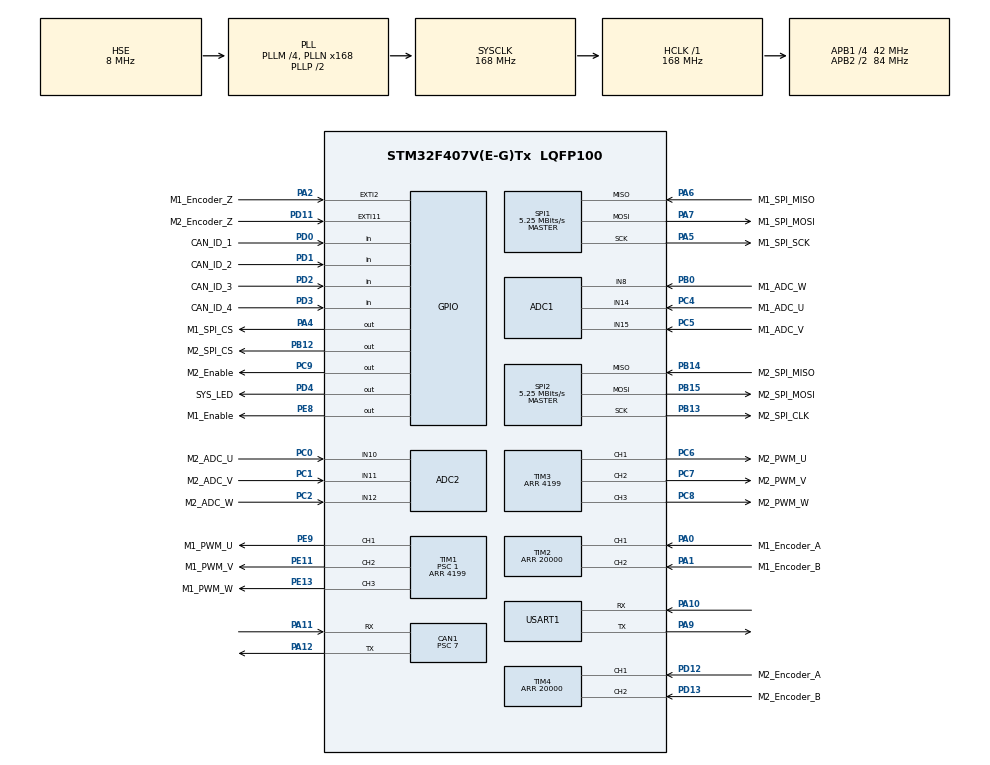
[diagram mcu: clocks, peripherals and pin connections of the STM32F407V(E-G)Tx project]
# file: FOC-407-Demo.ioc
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ADC1.Channel-0\#ChannelRegularConversion=ADC_CHANNEL_14
ADC1.Channel-1\#ChannelRegularConversion=ADC_CHANNEL_15
ADC1.Channel-2\#ChannelRegularConversion=ADC_CHANNEL_8
ADC1.ClockPrescaler=ADC_CLOCK_SYNC_PCLK_DIV4
ADC1.ContinuousConvMode=DISABLE
ADC1.DMAContinuousRequests=ENABLE
ADC1.EOCSelection=ADC_EOC_SEQ_CONV
ADC1.InjNumberOfConversion=0
ADC1.NbrOfConversion=3
ADC1.NbrOfConversionFlag=1
ADC1.Rank-0\#ChannelRegularConversion=1
ADC1.Rank-1\#ChannelRegularConversion=2
ADC1.Rank-2\#ChannelRegularConversion=3
ADC1.SamplingTime-0\#ChannelRegularConversion=ADC_SAMPLETIME_3CYCLES
ADC1.SamplingTime-1\#ChannelRegularConversion=ADC_SAMPLETIME_3CYCLES
ADC1.SamplingTime-2\#ChannelRegularConversion=ADC_SAMPLETIME_3CYCLES
ADC1.ScanConvMode=ENABLE
ADC1.master=1
ADC2.Channel-0\#ChannelRegularConversion=ADC_CHANNEL_10
ADC2.Channel-1\#ChannelRegularConversion=ADC_CHANNEL_11
ADC2.Channel-2\#ChannelRegularConversion=ADC_CHANNEL_12
ADC2.DMAContinuousRequests=ENABLE
ADC2.EOCSelection=ADC_EOC_SEQ_CONV
ADC2.NbrOfConversion=3
ADC2.NbrOfConversionFlag=1
ADC2.Rank-0\#ChannelRegularConversion=1
ADC2.Rank-1\#ChannelRegularConversion=2
ADC2.Rank-2\#ChannelRegularConversion=3
ADC2.SamplingTime-0\#ChannelRegularConversion=ADC_SAMPLETIME_3CYCLES
ADC2.SamplingTime-1\#ChannelRegularConversion=ADC_SAMPLETIME_3CYCLES
ADC2.SamplingTime-2\#ChannelRegularConversion=ADC_SAMPLETIME_3CYCLES
ADC2.ScanConvMode=ENABLE
CAN1.BS1=CAN_BS1_5TQ
CAN1.BS2=CAN_BS2_6TQ
CAN1.CalculateTimeQuantum=166.66666666666669
CAN1.Mode=CAN_MODE_NORMAL
CAN1.Prescaler=7
Dma.ADC1.0.Direction=DMA_PERIPH_TO_MEMORY
Dma.ADC1.0.FIFOMode=DMA_FIFOMODE_DISABLE
Dma.ADC1.0.Instance=DMA2_Stream0
Dma.ADC1.0.MemDataAlignment=DMA_MDATAALIGN_WORD
Dma.ADC1.0.MemInc=DMA_MINC_ENABLE
Dma.ADC1.0.Mode=DMA_CIRCULAR
Dma.ADC1.0.PeriphDataAlignment=DMA_PDATAALIGN_WORD
Dma.ADC1.0.PeriphInc=DMA_PINC_DISABLE
Dma.ADC1.0.Priority=DMA_PRIORITY_HIGH
Dma.ADC2.1.Direction=DMA_PERIPH_TO_MEMORY
Dma.ADC2.1.FIFOMode=DMA_FIFOMODE_DISABLE
Dma.ADC2.1.Instance=DMA2_Stream2
Dma.ADC2.1.MemDataAlignment=DMA_MDATAALIGN_WORD
Dma.ADC2.1.MemInc=DMA_MINC_ENABLE
Dma.ADC2.1.Mode=DMA_CIRCULAR
Dma.ADC2.1.PeriphDataAlignment=DMA_PDATAALIGN_WORD
Dma.ADC2.1.PeriphInc=DMA_PINC_DISABLE
Dma.ADC2.1.Priority=DMA_PRIORITY_HIGH
Dma.Request0=ADC1
Dma.Request1=ADC2
Mcu.Family=STM32F4
Mcu.Name=STM32F407V(E-G)Tx
Mcu.Package=LQFP100
NVIC.CAN1_RX0_IRQn=true\:7\:0\:true\:false\:true\:true\:true
NVIC.DMA2_Stream0_IRQn=true\:3\:0\:true\:false\:true\:true\:true
NVIC.DMA2_Stream2_IRQn=true\:5\:0\:true\:false\:true\:false\:true
NVIC.EXTI15_10_IRQn=true\:2\:0\:true\:false\:true\:true\:true
NVIC.EXTI2_IRQn=true\:1\:0\:true\:false\:true\:true\:true
NVIC.PriorityGroup=NVIC_PRIORITYGROUP_4
NVIC.TIM1_UP_TIM10_IRQn=true\:4\:0\:true\:false\:true\:true\:true
NVIC.TIM3_IRQn=true\:6\:0\:true\:false\:true\:true\:true
NVIC.USART1_IRQn=true\:8\:0\:true\:false\:true\:true\:true
PA0-WKUP.GPIO_Label=M1_Encoder_A
PA0-WKUP.Signal=S_TIM2_CH1_ETR
PA1.GPIO_Label=M1_Encoder_B
PA1.Signal=S_TIM2_CH2
PA10.Mode=Asynchronous
PA10.Signal=USART1_RX
PA11.Mode=Master
PA11.Signal=CAN1_RX
PA12.Mode=Master
PA12.Signal=CAN1_TX
PA13.Mode=Serial_Wire
PA13.Signal=SYS_JTMS-SWDIO
PA14.Mode=Serial_Wire
PA14.Signal=SYS_JTCK-SWCLK
PA2.GPIO_Label=M1_Encoder_Z
PA2.Signal=GPXTI2
PA4.GPIO_Label=M1_SPI_CS
PA4.GPIO_PuPd=GPIO_PULLUP
PA4.GPIO_Speed=GPIO_SPEED_FREQ_HIGH
PA4.PinState=GPIO_PIN_SET
PA4.Signal=GPIO_Output
PA5.GPIO_Label=M1_SPI_SCK
PA5.Mode=Full_Duplex_Master
PA5.Signal=SPI1_SCK
PA6.GPIO_Label=M1_SPI_MISO
PA6.Mode=Full_Duplex_Master
PA6.Signal=SPI1_MISO
PA7.GPIO_Label=M1_SPI_MOSI
PA7.Mode=Full_Duplex_Master
PA7.Signal=SPI1_MOSI
PA9.Mode=Asynchronous
PA9.Signal=USART1_TX
PB0.GPIO_Label=M1_ADC_W
PB0.Signal=ADCx_IN8
PB12.GPIO_Label=M2_SPI_CS
PB12.GPIO_PuPd=GPIO_PULLUP
PB12.GPIO_Speed=GPIO_SPEED_FREQ_HIGH
PB12.PinState=GPIO_PIN_SET
PB12.Signal=GPIO_Output
PB13.GPIO_Label=M2_SPI_CLK
PB13.Mode=Full_Duplex_Master
PB13.Signal=SPI2_SCK
PB14.GPIO_Label=M2_SPI_MISO
PB14.Mode=Full_Duplex_Master
PB14.Signal=SPI2_MISO
PB15.GPIO_Label=M2_SPI_MOSI
PB15.Mode=Full_Duplex_Master
PB15.Signal=SPI2_MOSI
PC0.GPIO_Label=M2_ADC_U
PC0.Signal=ADCx_IN10
PC1.GPIO_Label=M2_ADC_V
PC1.Signal=ADCx_IN11
PC2.GPIO_Label=M2_ADC_W
PC2.Signal=ADCx_IN12
PC4.GPIO_Label=M1_ADC_U
PC4.Signal=ADCx_IN14
PC5.GPIO_Label=M1_ADC_V
PC5.Signal=ADCx_IN15
PC6.GPIO_Label=M2_PWM_U
PC6.Signal=S_TIM3_CH1
PC7.GPIO_Label=M2_PWM_V
PC7.Signal=S_TIM3_CH2
PC8.GPIO_Label=M2_PWM_W
PC8.Signal=S_TIM3_CH3
PC9.GPIO_Label=M2_Enable
PC9.Signal=GPIO_Output
PD0.GPIO_Label=CAN_ID_1
PD0.GPIO_PuPd=GPIO_PULLUP
PD0.Signal=GPIO_Input
PD1.GPIO_Label=CAN_ID_2
PD1.GPIO_PuPd=GPIO_PULLUP
PD1.Signal=GPIO_Input
PD11.GPIO_Label=M2_Encoder_Z
PD11.Signal=GPXTI11
PD12.GPIO_Label=M2_Encoder_A
PD12.Signal=S_TIM4_CH1
PD13.GPIO_Label=M2_Encoder_B
PD13.Signal=S_TIM4_CH2
PD2.GPIO_Label=CAN_ID_3
PD2.GPIO_PuPd=GPIO_PULLUP
PD2.Signal=GPIO_Input
PD3.GPIO_Label=CAN_ID_4
PD3.GPIO_PuPd=GPIO_PULLUP
PD3.Signal=GPIO_Input
PD4.GPIO_Label=SYS_LED
PD4.Signal=GPIO_Output
PE11.GPIO_Label=M1_PWM_V
PE11.Signal=S_TIM1_CH2
PE13.GPIO_Label=M1_PWM_W
PE13.Signal=S_TIM1_CH3
PE8.GPIO_Label=M1_Enable
PE8.Signal=GPIO_Output
PE9.GPIO_Label=M1_PWM_U
PE9.Signal=S_TIM1_CH1
PH0-OSC_IN.Mode=HSE-External-Oscillator
PH0-OSC_IN.Signal=RCC_OSC_IN
PH1-OSC_OUT.Mode=HSE-External-Oscillator
PH1-OSC_OUT.Signal=RCC_OSC_OUT
ProjectManager.HeapSize=0x200
ProjectManager.StackSize=0x400
ProjectManager.TargetToolchain=MDK-ARM V5.27
RCC.48MHZClocksFreq_Value=84000000
RCC.AHBFreq_Value=168000000
RCC.APB1CLKDivider=RCC_HCLK_DIV4
RCC.APB1Freq_Value=42000000
RCC.APB1TimFreq_Value=84000000
RCC.APB2CLKDivider=RCC_HCLK_DIV2
RCC.APB2Freq_Value=84000000
RCC.APB2TimFreq_Value=168000000
RCC.CortexFreq_Value=168000000
RCC.HCLKFreq_Value=168000000
RCC.HSE_VALUE=8000000
RCC.HSI_VALUE=16000000
RCC.LSE_VALUE=32768
RCC.PLLM=4
RCC.PLLN=168
RCC.PLLSourceVirtual=RCC_PLLSOURCE_HSE
RCC.SYSCLKFreq_VALUE=168000000
RCC.SYSCLKSource=RCC_SYSCLKSOURCE_PLLCLK
RCC.VCOOutputFreq_Value=336000000
SH.ADCx_IN10.0=ADC2_IN10,IN10
SH.ADCx_IN11.0=ADC2_IN11,IN11
SH.ADCx_IN12.0=ADC2_IN12,IN12
SH.ADCx_IN14.0=ADC1_IN14,IN14
SH.ADCx_IN15.0=ADC1_IN15,IN15
SH.ADCx_IN8.0=ADC1_IN8,IN8
SH.S_TIM1_CH1.0=TIM1_CH1,PWM Generation1 CH1
SH.S_TIM1_CH2.0=TIM1_CH2,PWM Generation2 CH2
SH.S_TIM1_CH3.0=TIM1_CH3,PWM Generation3 CH3
SH.S_TIM2_CH1_ETR.0=TIM2_CH1,Encoder_Interface
SH.S_TIM2_CH2.0=TIM2_CH2,Encoder_Interface
SH.S_TIM3_CH1.0=TIM3_CH1,PWM Generation1 CH1
SH.S_TIM3_CH2.0=TIM3_CH2,PWM Generation2 CH2
SH.S_TIM3_CH3.0=TIM3_CH3,PWM Generation3 CH3
SH.S_TIM4_CH1.0=TIM4_CH1,Encoder_Interface
SH.S_TIM4_CH2.0=TIM4_CH2,Encoder_Interface
SPI1.BaudRatePrescaler=SPI_BAUDRATEPRESCALER_16
SPI1.CLKPhase=SPI_PHASE_2EDGE
SPI1.CalculateBaudRate=5.25 MBits/s
SPI1.DataSize=SPI_DATASIZE_16BIT
SPI1.Direction=SPI_DIRECTION_2LINES
SPI1.Mode=SPI_MODE_MASTER
SPI1.VirtualType=VM_MASTER
SPI2.BaudRatePrescaler=SPI_BAUDRATEPRESCALER_8
SPI2.CLKPhase=SPI_PHASE_2EDGE
SPI2.CalculateBaudRate=5.25 MBits/s
SPI2.DataSize=SPI_DATASIZE_16BIT
SPI2.Direction=SPI_DIRECTION_2LINES
SPI2.Mode=SPI_MODE_MASTER
SPI2.VirtualType=VM_MASTER
TIM1.AutoReloadPreload=TIM_AUTORELOAD_PRELOAD_ENABLE
TIM1.Channel-PWM\ Generation1\ CH1=TIM_CHANNEL_1
TIM1.Channel-PWM\ Generation2\ CH2=TIM_CHANNEL_2
TIM1.Channel-PWM\ Generation3\ CH3=TIM_CHANNEL_3
TIM1.CounterMode=TIM_COUNTERMODE_CENTERALIGNED2
TIM1.Period=4199
TIM1.Prescaler=1
TIM1.TIM_MasterOutputTrigger=TIM_TRGO_UPDATE
TIM1.TIM_MasterSlaveMode=TIM_MASTERSLAVEMODE_ENABLE
TIM2.EncoderMode=TIM_ENCODERMODE_TI1
TIM2.Period=20000
TIM3.AutoReloadPreload=TIM_AUTORELOAD_PRELOAD_ENABLE
TIM3.Channel-PWM\ Generation1\ CH1=TIM_CHANNEL_1
TIM3.Channel-PWM\ Generation2\ CH2=TIM_CHANNEL_2
TIM3.Channel-PWM\ Generation3\ CH3=TIM_CHANNEL_3
TIM3.CounterMode=TIM_COUNTERMODE_CENTERALIGNED2
TIM3.Period=4199
TIM3.TIM_MasterOutputTrigger=TIM_TRGO_UPDATE
TIM3.TIM_MasterSlaveMode=TIM_MASTERSLAVEMODE_DISABLE
TIM4.EncoderMode=TIM_ENCODERMODE_TI1
TIM4.Period=20000
USART1.VirtualMode=VM_ASYNC
VP_TIM3_VS_ClockSourceITR.Mode=TriggerSource_ITR0
VP_TIM3_VS_ControllerModeTrigger.Mode=Trigger Mode
board=custom

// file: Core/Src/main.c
/* USER CODE BEGIN Header */
/**
  ******************************************************************************
  * @file           : main.c
  * @brief          : Main program body
  ******************************************************************************
  * @attention
  *
  * <h2><center>&copy; Copyright (c) 2021 STMicroelectronics.
  * All rights reserved.</center></h2>
  *
  * This software component is licensed by ST under BSD 3-Clause license,
  * the "License"; You may not use this file except in compliance with the
  * License. You may obtain a copy of the License at:
  *                        opensource.org/licenses/BSD-3-Clause
  *
  ******************************************************************************
  */
/* USER CODE END Header */
#include "main.h"
#include "adc.h"
#include "can.h"
#include "dma.h"
#include "spi.h"
#include "tim.h"
#include "usart.h"
#include "gpio.h"

/* USER CODE BEGIN Includes */
#include "APPMain.h"
#include "timer.h"
/* USER CODE END Includes */

void SystemClock_Config(void);

int main(void)
{

  /* MCU Configuration--------------------------------------------------------*/

  /* Reset of all peripherals, Initializes the Flash interface and the Systick. */
  HAL_Init();

  /* Configure the system clock */
  SystemClock_Config();

  /* Initialize all configured peripherals */
  MX_GPIO_Init();
  MX_DMA_Init();
  MX_ADC1_Init();
  MX_ADC2_Init();
  MX_SPI1_Init();
  MX_SPI2_Init();
  MX_CAN1_Init();
  MX_TIM1_Init();
  MX_TIM2_Init();
  MX_TIM3_Init();
  MX_TIM4_Init();
  MX_USART1_UART_Init();
  /* USER CODE BEGIN 2 */
  APPMain_Init();
  /* USER CODE END 2 */

  /* Infinite loop */
  /* USER CODE BEGIN WHILE */
  while (1)
  {
	  APPMain_Loop();
    /* USER CODE END WHILE */

  }
}

void SystemClock_Config(void)
{
  RCC_OscInitTypeDef RCC_OscInitStruct = {0};
  RCC_ClkInitTypeDef RCC_ClkInitStruct = {0};

  /** Configure the main internal regulator output voltage
  */
  __HAL_RCC_PWR_CLK_ENABLE();
  __HAL_PWR_VOLTAGESCALING_CONFIG(PWR_REGULATOR_VOLTAGE_SCALE1);
  /** Initializes the RCC Oscillators according to the specified parameters
  * in the RCC_OscInitTypeDef structure.
  */
  RCC_OscInitStruct.OscillatorType = RCC_OSCILLATORTYPE_HSE;
  RCC_OscInitStruct.HSEState = RCC_HSE_ON;
  RCC_OscInitStruct.PLL.PLLState = RCC_PLL_ON;
  RCC_OscInitStruct.PLL.PLLSource = RCC_PLLSOURCE_HSE;
  RCC_OscInitStruct.PLL.PLLM = 4;
  RCC_OscInitStruct.PLL.PLLN = 168;
  RCC_OscInitStruct.PLL.PLLP = RCC_PLLP_DIV2;
  RCC_OscInitStruct.PLL.PLLQ = 4;
  if (HAL_RCC_OscConfig(&RCC_OscInitStruct) != HAL_OK)
  {
    Error_Handler();
  }
  /** Initializes the CPU, AHB and APB buses clocks
  */
  RCC_ClkInitStruct.ClockType = RCC_CLOCKTYPE_HCLK|RCC_CLOCKTYPE_SYSCLK
                              |RCC_CLOCKTYPE_PCLK1|RCC_CLOCKTYPE_PCLK2;
  RCC_ClkInitStruct.SYSCLKSource = RCC_SYSCLKSOURCE_PLLCLK;
  RCC_ClkInitStruct.AHBCLKDivider = RCC_SYSCLK_DIV1;
  RCC_ClkInitStruct.APB1CLKDivider = RCC_HCLK_DIV4;
  RCC_ClkInitStruct.APB2CLKDivider = RCC_HCLK_DIV2;

  if (HAL_RCC_ClockConfig(&RCC_ClkInitStruct, FLASH_LATENCY_5) != HAL_OK)
  {
    Error_Handler();
  }
}

void Error_Handler(void)
{
}

/************************ (C) COPYRIGHT STMicroelectronics *****END OF FILE****/
